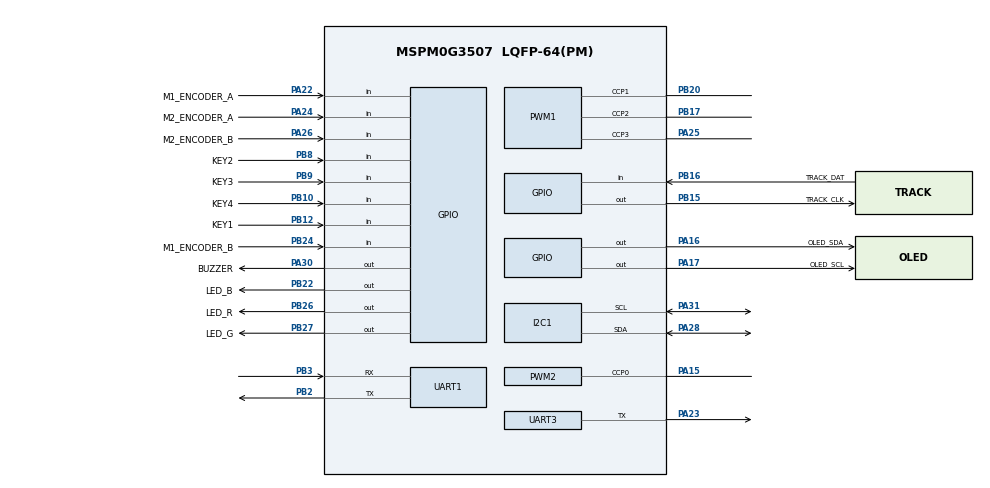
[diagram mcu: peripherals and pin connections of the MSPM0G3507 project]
/**
 * AI AGENTS: Do not edit this file directly. There is no validation or error feedback when
 * editing manually — mistakes will be silent until the file is loaded in SysConfig.
 * Use the SysConfig MCP server instead to make changes with immediate error reporting.
 *
 * These arguments were used when this file was generated. They will be automatically applied on subsequent loads
 * via the GUI or CLI. Run CLI with '--help' for additional information on how to override these arguments.
 * @cliArgs --device "MSPM0G350X" --part "Default" --package "LQFP-64(PM)" --product "mspm0_sdk@2.10.00.04"
 * @v2CliArgs --device "MSPM0G3507" --package "LQFP-64(PM)" --product "mspm0_sdk@2.10.00.04"
 * @versions {"tool":"1.28.0+4712"}
 */

/**
 * Import the modules used in this configuration.
 */
const Board         = scripting.addModule("/ti/driverlib/Board");
const GPIO          = scripting.addModule("/ti/driverlib/GPIO", {}, false);
const GPIO1         = GPIO.addInstance();
const GPIO2         = GPIO.addInstance();
const I2C           = scripting.addModule("/ti/driverlib/I2C", {}, false);
const I2C1          = I2C.addInstance();
const PWM           = scripting.addModule("/ti/driverlib/PWM", {}, false);
const PWM1          = PWM.addInstance();
const PWM2          = PWM.addInstance();
const SYSCTL        = scripting.addModule("/ti/driverlib/SYSCTL");
const UART          = scripting.addModule("/ti/driverlib/UART", {}, false);
const UART1         = UART.addInstance();
const UART2         = UART.addInstance();
const UART3         = UART.addInstance();
const ProjectConfig = scripting.addModule("/ti/project_config/ProjectConfig");

/**
 * Write custom configuration values to the imported modules.
 */
const divider6       = system.clockTree["PLL_CLK2X_DIV"];
divider6.divideValue = 4;

const divider7       = system.clockTree["PLL_PDIV"];
divider7.divideValue = 2;

const divider9       = system.clockTree["UDIV"];
divider9.divideValue = 2;

const multiplier2         = system.clockTree["PLL_QDIV"];
multiplier2.multiplyValue = 10;

const mux8       = system.clockTree["HSCLKMUX"];
mux8.inputSelect = "HSCLKMUX_SYSPLL2X";

const mfclkGate  = system.clockTree["MFCLKGATE"];
mfclkGate.enable = true;


GPIO1.$name                              = "PORTB";
GPIO1.port                               = "PORTB";
GPIO1.associatedPins.create(10);
GPIO1.associatedPins[0].assignedPin      = "26";
GPIO1.associatedPins[0].$name            = "LED_R";
GPIO1.associatedPins[0].pin.$assign      = "PB26";
GPIO1.associatedPins[1].assignedPin      = "27";
GPIO1.associatedPins[1].$name            = "LED_G";
GPIO1.associatedPins[1].pin.$assign      = "PB27";
GPIO1.associatedPins[2].assignedPin      = "22";
GPIO1.associatedPins[2].$name            = "LED_B";
GPIO1.associatedPins[2].pin.$assign      = "PB22";
GPIO1.associatedPins[3].direction        = "INPUT";
GPIO1.associatedPins[3].$name            = "KEY1";
GPIO1.associatedPins[3].assignedPin      = "12";
GPIO1.associatedPins[3].pin.$assign      = "PB12";
GPIO1.associatedPins[4].direction        = "INPUT";
GPIO1.associatedPins[4].$name            = "KEY2";
GPIO1.associatedPins[4].assignedPin      = "8";
GPIO1.associatedPins[4].internalResistor = "PULL_UP";
GPIO1.associatedPins[4].pin.$assign      = "PB8";
GPIO1.associatedPins[5].direction        = "INPUT";
GPIO1.associatedPins[5].$name            = "KEY3";
GPIO1.associatedPins[5].assignedPin      = "9";
GPIO1.associatedPins[5].pin.$assign      = "PB9";
GPIO1.associatedPins[6].direction        = "INPUT";
GPIO1.associatedPins[6].$name            = "KEY4";
GPIO1.associatedPins[6].assignedPin      = "10";
GPIO1.associatedPins[6].pin.$assign      = "PB10";
GPIO1.associatedPins[7].$name            = "M1_ENCODER_B";
GPIO1.associatedPins[7].assignedPin      = "24";
GPIO1.associatedPins[7].direction        = "INPUT";
GPIO1.associatedPins[7].internalResistor = "PULL_UP";
GPIO1.associatedPins[7].interruptEn      = true;
GPIO1.associatedPins[7].polarity         = "RISE_FALL";
GPIO1.associatedPins[7].pin.$assign      = "PB24";
GPIO1.associatedPins[8].$name            = "TRACK_CLK";
GPIO1.associatedPins[8].assignedPin      = "15";
GPIO1.associatedPins[8].pin.$assign      = "PB15";
GPIO1.associatedPins[9].$name            = "TRACK_DAT";
GPIO1.associatedPins[9].assignedPin      = "16";
GPIO1.associatedPins[9].direction        = "INPUT";
GPIO1.associatedPins[9].pin.$assign      = "PB16";
GPIO2.$name                              = "PORTA";
GPIO2.port                               = "PORTA";
GPIO2.associatedPins.create(6);
GPIO2.associatedPins[0].$name            = "OLED_SDA";
GPIO2.associatedPins[0].assignedPin      = "16";
GPIO2.associatedPins[0].pin.$assign      = "PA16";
GPIO2.associatedPins[1].$name            = "OLED_SCL";
GPIO2.associatedPins[1].assignedPin      = "17";
GPIO2.associatedPins[1].pin.$assign      = "PA17";
GPIO2.associatedPins[2].$name            = "M1_ENCODER_A";
GPIO2.associatedPins[2].assignedPin      = "22";
GPIO2.associatedPins[2].direction        = "INPUT";
GPIO2.associatedPins[2].internalResistor = "PULL_UP";
GPIO2.associatedPins[2].interruptEn      = true;
GPIO2.associatedPins[2].polarity         = "RISE_FALL";
GPIO2.associatedPins[2].pin.$assign      = "PA22";
GPIO2.associatedPins[3].$name            = "M2_ENCODER_A";
GPIO2.associatedPins[3].assignedPin      = "24";
GPIO2.associatedPins[3].direction        = "INPUT";
GPIO2.associatedPins[3].internalResistor = "PULL_UP";
GPIO2.associatedPins[3].interruptEn      = true;
GPIO2.associatedPins[3].polarity         = "RISE_FALL";
GPIO2.associatedPins[3].pin.$assign      = "PA24";
GPIO2.associatedPins[4].$name            = "M2_ENCODER_B";
GPIO2.associatedPins[4].assignedPin      = "26";
GPIO2.associatedPins[4].direction        = "INPUT";
GPIO2.associatedPins[4].internalResistor = "PULL_UP";
GPIO2.associatedPins[4].interruptEn      = true;
GPIO2.associatedPins[4].polarity         = "RISE_FALL";
GPIO2.associatedPins[4].pin.$assign      = "PA26";
GPIO2.associatedPins[5].$name            = "BUZZER";
GPIO2.associatedPins[5].assignedPin      = "30";
GPIO2.associatedPins[5].pin.$assign      = "PA30";

I2C1.$name                     = "I2C_0";
I2C1.basicEnableController     = true;
I2C1.peripheral.sdaPin.$assign = "PA28";
I2C1.peripheral.sclPin.$assign = "PA31";
I2C1.sdaPinConfig.$name        = "ti_driverlib_gpio_GPIOPinGeneric13";
I2C1.sclPinConfig.$name        = "ti_driverlib_gpio_GPIOPinGeneric14";

PWM1.$name                         = "Motor_PWM1";
PWM1.timerStartTimer               = true;
PWM1.pwmMode                       = "EDGE_ALIGN_UP";
PWM1.timerCount                    = 3000;
PWM1.clockDivider                  = 8;
PWM1.ccIndex                       = [1,2,3];
PWM1.peripheral.$assign            = "TIMA0";
PWM1.peripheral.ccp1Pin.$assign    = "PB20";
PWM1.peripheral.ccp2Pin.$assign    = "PB17";
PWM1.peripheral.ccp3Pin.$assign    = "PA25";
PWM1.PWM_CHANNEL_1.$name           = "M1_PWM2";
PWM1.PWM_CHANNEL_1.dutyCycle       = 0;
PWM1.PWM_CHANNEL_2.$name           = "M2_PWM1";
PWM1.PWM_CHANNEL_2.dutyCycle       = 0;
PWM1.PWM_CHANNEL_3.$name           = "M2_PWM2";
PWM1.PWM_CHANNEL_3.dutyCycle       = 0;

PWM2.$name                         = "Motor_PWM2";
PWM2.timerStartTimer               = true;
PWM2.pwmMode                       = "EDGE_ALIGN_UP";
PWM2.timerCount                    = 3000;
PWM2.clockDivider                  = 8;
PWM2.ccIndex                       = [0];
PWM2.peripheral.$assign            = "TIMA1";
PWM2.peripheral.ccp0Pin.$assign    = "PA15";
PWM2.PWM_CHANNEL_0.$name           = "M1_PWM1";
PWM2.PWM_CHANNEL_0.dutyCycle       = 0;

SYSCTL.MFCLKEn     = true;
SYSCTL.clockTreeEn = true;

UART1.targetBaudRate                   = 115200;
UART1.rxFifoThreshold                  = "DL_UART_RX_FIFO_LEVEL_ONE_ENTRY";
UART1.enableDMARX                      = false;
UART1.enableDMATX                      = false;
UART1.enabledInterrupts                = ["RX"];
UART1.$name                            = "GYRO_UART";
UART1.uartClkSrc                       = "MFCLK";
UART1.peripheral.$assign               = "UART3";
UART1.peripheral.rxPin.$assign         = "PB3";
UART1.peripheral.txPin.$assign         = "PB2";
UART1.txPinConfig.direction            = scripting.forceWrite("OUTPUT");
UART1.txPinConfig.hideOutputInversion  = scripting.forceWrite(false);
UART1.txPinConfig.onlyInternalResistor = scripting.forceWrite(false);
UART1.txPinConfig.passedPeripheralType = scripting.forceWrite("Digital");
UART1.txPinConfig.$name                = "ti_driverlib_gpio_GPIOPinGeneric11";
UART1.rxPinConfig.hideOutputInversion  = scripting.forceWrite(false);
UART1.rxPinConfig.onlyInternalResistor = scripting.forceWrite(false);
UART1.rxPinConfig.passedPeripheralType = scripting.forceWrite("Digital");
UART1.rxPinConfig.$name                = "ti_driverlib_gpio_GPIOPinGeneric12";

UART2.targetBaudRate                   = 115200;
UART2.enabledInterrupts                = ["RX"];
UART2.$name                            = "CAM_UART";
UART2.txPinConfig.direction            = scripting.forceWrite("OUTPUT");
UART2.txPinConfig.hideOutputInversion  = scripting.forceWrite(false);
UART2.txPinConfig.onlyInternalResistor = scripting.forceWrite(false);
UART2.txPinConfig.passedPeripheralType = scripting.forceWrite("Digital");
UART2.txPinConfig.$name                = "ti_driverlib_gpio_GPIOPinGeneric7";
UART2.rxPinConfig.hideOutputInversion  = scripting.forceWrite(false);
UART2.rxPinConfig.onlyInternalResistor = scripting.forceWrite(false);
UART2.rxPinConfig.passedPeripheralType = scripting.forceWrite("Digital");
UART2.rxPinConfig.$name                = "ti_driverlib_gpio_GPIOPinGeneric8";

UART3.direction                        = "TX";
UART3.targetBaudRate                   = 115200;
UART3.$name                            = "DEBUG_UART";
UART3.peripheral.$assign               = "UART2";
UART3.peripheral.txPin.$assign         = "PA23";
UART3.txPinConfig.direction            = scripting.forceWrite("OUTPUT");
UART3.txPinConfig.hideOutputInversion  = scripting.forceWrite(false);
UART3.txPinConfig.onlyInternalResistor = scripting.forceWrite(false);
UART3.txPinConfig.passedPeripheralType = scripting.forceWrite("Digital");
UART3.txPinConfig.$name                = "ti_driverlib_gpio_GPIOPinGeneric15";

ProjectConfig.genDisable = true;
scripting.suppress("Project Configuration File generation is disabled for this project\\. SysConfig Project Migration is not currently supported for this project\\.", ProjectConfig);

/**
 * Pinmux solution for unlocked pins/peripherals. This ensures that minor changes to the automatic solver in a future
 * version of the tool will not impact the pinmux you originally saw.  These lines can be completely deleted in order to
 * re-solve from scratch.
 */
Board.peripheral.$suggestSolution            = "DEBUGSS";
Board.peripheral.swclkPin.$suggestSolution   = "PA20";
Board.peripheral.swdioPin.$suggestSolution   = "PA19";
I2C1.peripheral.$suggestSolution             = "I2C0";
UART2.peripheral.$suggestSolution            = "UART0";
UART2.peripheral.rxPin.$suggestSolution      = "PA11";
UART2.peripheral.txPin.$suggestSolution      = "PA10";
